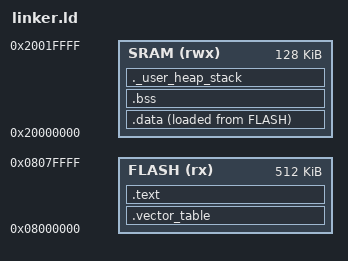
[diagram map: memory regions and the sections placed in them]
/* Linker Script for STM32F407VG ARM Cortex-M4 Bare-Metal Firmware */

MEMORY
{
    FLASH (rx)  : ORIGIN = 0x08000000, LENGTH = 512K
    SRAM  (rwx) : ORIGIN = 0x20000000, LENGTH = 128K
}

ENTRY(Reset_Handler)

SECTIONS
{
    .vector_table :
    {
        . = ALIGN(4);
        KEEP(*(.vector_table))
        . = ALIGN(4);
    } > FLASH

    .text :
    {
        . = ALIGN(4);
        *(.text)
        *(.text*)
        *(.rodata)
        *(.rodata*)
        . = ALIGN(4);
        _etext = .;
    } > FLASH

    _sidata = LOADADDR(.data);

    .data :
    {
        . = ALIGN(4);
        _sdata = .;
        *(.data)
        *(.data*)
        . = ALIGN(4);
        _edata = .;
    } > SRAM AT > FLASH

    .bss :
    {
        . = ALIGN(4);
        _sbss = .;
        *(.bss)
        *(.bss*)
        *(COMMON)
        . = ALIGN(4);
        _ebss = .;
    } > SRAM

    ._user_heap_stack :
    {
        . = ALIGN(8);
        . = . + 0x800; /* 2048 bytes stack space */
        . = ALIGN(8);
    } > SRAM
}
